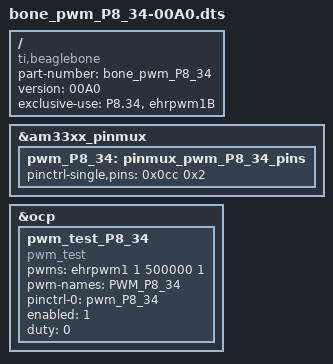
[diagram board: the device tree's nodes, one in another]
/*
 * Copyright (C) 2013 CircuitCo
 * Copyright (C) 2013 Texas Instruments
 *
 * This program is free software; you can redistribute it and/or modify
 * it under the terms of the GNU General Public License version 2 as
 * published by the Free Software Foundation.
 */
/dts-v1/;
/plugin/;

/ {
	compatible = "ti,beaglebone", "ti,beaglebone-black";

	/* identification */
	part-number = "bone_pwm_P8_34";
	version = "00A0";

	/* state the resources this cape uses */
	exclusive-use =
		/* the pin header uses */
		"P8.34",		/* pwm: ehrpwm1B */
		/* the hardware IP uses */
		"ehrpwm1B";

	fragment@0 {
		target = <&am33xx_pinmux>;
		__overlay__ {
			pwm_P8_34: pinmux_pwm_P8_34_pins {
				pinctrl-single,pins = <0x0cc  0x2>; /* P8_34 (ZCZ ball U4) | MODE 2 */
			};
		};
	};

	fragment@1 {
		target = <&ocp>;
		__overlay__ {
			pwm_test_P8_34 {
				compatible	= "pwm_test";
				pwms 		= <&ehrpwm1 1 500000 1>;
				pwm-names 	= "PWM_P8_34";
			    pinctrl-names	= "default";
			    pinctrl-0	= <&pwm_P8_34>;
				enabled		= <1>;
				duty		= <0>;
				status 		= "okay";
			};
		};
	};
};
